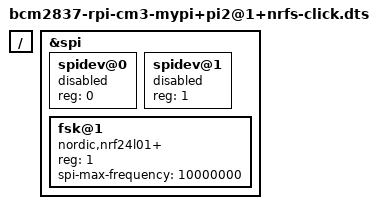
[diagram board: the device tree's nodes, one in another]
/* SPDX-License-Identifier: GPL-2.0-or-later OR MIT */
/*
 * Copyright (c) 2019 Andreas Färber
 */

/dts-v1/;
/plugin/;

/ {
	#address-cells = <1>;
	#size-cells = <0>;

	fragment@0 {
		reg = <0>;

		target = <&spi>;

		__overlay__ {
			status = "okay";

			#address-cells = <1>;
			#size-cells = <0>;

			spidev@0 {
				reg = <0>;
				status = "disabled";
			};

			spidev@1 {
				reg = <1>;
				status = "disabled";
			};

			fsk@1 {
				compatible = "nordic,nrf24l01+";
				reg = <1>;
				spi-max-frequency = <10000000>;
			};
		};
	};
};
